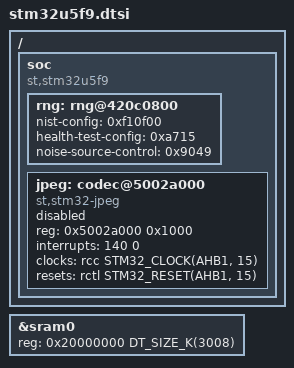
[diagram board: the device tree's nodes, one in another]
/*
 * Copyright (c) 2025 Harris Tomy
 *
 * SPDX-License-Identifier: Apache-2.0
 */

#include <st/u5/stm32u599.dtsi>

/ {
	soc {
		compatible = "st,stm32u5f9", "st,stm32u5", "simple-bus";

		rng: rng@420c0800 {
			nist-config = <0xf10f00>;
			health-test-config = <0xa715>;
			noise-source-control = <0x9049>;
		};

		jpeg: codec@5002a000 {
			compatible = "st,stm32-jpeg";
			reg = <0x5002a000 0x1000>;
			interrupts = <140 0>;
			clocks = <&rcc STM32_CLOCK(AHB1, 15)>;
			resets = <&rctl STM32_RESET(AHB1, 15)>;
			status = "disabled";
		};
	};
};

&sram0 {
	/* SRAM1 + SRAM2 + SRAM3 + SRAM5 + SRAM6 */
	/* 768K + 64K + 832K + 832K + 512K */
	reg = <0x20000000 DT_SIZE_K(3008)>;
};
